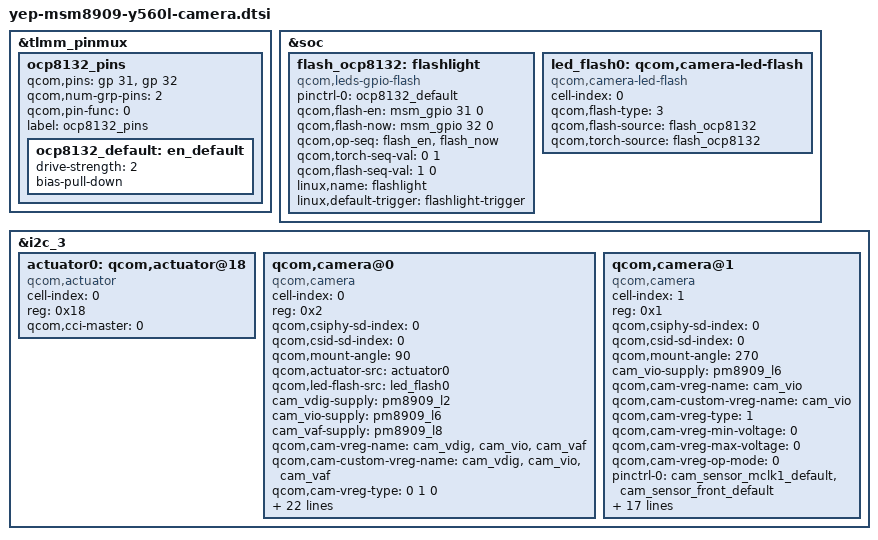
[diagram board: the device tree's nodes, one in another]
/*
 * Copyright (c) 2014, The Linux Foundation. All rights reserved.
 *
 * This program is free software; you can redistribute it and/or modify
 * it under the terms of the GNU General Public License version 2 and
 * only version 2 as published by the Free Software Foundation.
 *
 * This program is distributed in the hope that it will be useful,
 * but WITHOUT ANY WARRANTY; without even the implied warranty of
 * MERCHANTABILITY or FITNESS FOR A PARTICULAR PURPOSE.  See the
 * GNU General Public License for more details.
 */
 
/*  Date            Author          Why
    2014-01-12      litao2          creat
*/ 
 
&tlmm_pinmux {
	ocp8132_pins {
		qcom,pins = <&gp 31>, <&gp 32>;
		qcom,num-grp-pins = <2>;
		qcom,pin-func = <0>;
		label = "ocp8132_pins";
		ocp8132_default: en_default {
		drive-strength = <2>;
		bias-pull-down;
		};
	};
};

&soc {
	flash_ocp8132:flashlight {
		compatible = "qcom,leds-gpio-flash";
		status = "okay";
		pinctrl-names = "flash_default";
		pinctrl-0 = <&ocp8132_default>;
		qcom,flash-en = <&msm_gpio 31 0>;
		qcom,flash-now = <&msm_gpio 32 0>;
		qcom,op-seq = "flash_en", "flash_now";
		qcom,torch-seq-val = <0 1>;
		qcom,flash-seq-val = <1 0>;
		linux,name = "flashlight";
		linux,default-trigger = "flashlight-trigger";
	};
	led_flash0: qcom,camera-led-flash {
		cell-index = <0>;
		compatible = "qcom,camera-led-flash";
		qcom,flash-type = <3>;
		qcom,flash-source = <&flash_ocp8132>;
		qcom,torch-source = <&flash_ocp8132>;
	};
};

&i2c_3 {

	actuator0: qcom,actuator@18 {
		cell-index = <0>;
		reg = <0x18>;
		compatible = "qcom,actuator";
		qcom,cci-master = <0>;
	};
	
	qcom,camera@0 {
		cell-index = <0>;
		compatible = "qcom,camera";
		reg = <0x2>;
		qcom,csiphy-sd-index = <0>;
		qcom,csid-sd-index = <0>;
		qcom,mount-angle = <90>;
		qcom,actuator-src = <&actuator0>;
		qcom,led-flash-src = <&led_flash0>;
		cam_vdig-supply = <&pm8909_l2>;
		cam_vio-supply = <&pm8909_l6>;
		cam_vaf-supply = <&pm8909_l8>;
		qcom,cam-vreg-name = "cam_vdig","cam_vio","cam_vaf";
		qcom,cam-custom-vreg-name = "cam_vdig","cam_vio","cam_vaf";
		qcom,cam-vreg-type = <0 1 0>;
		qcom,cam-vreg-min-voltage = <1200000 0 2850000>;
		qcom,cam-vreg-max-voltage = <1200000 0 2900000>;
		qcom,cam-vreg-op-mode = <200000 0 100000>;
		pinctrl-names = "cam_default", "cam_suspend";
		pinctrl-0 = <&cam_sensor_mclk0_default
				&cam_sensor_rear_default>;
		pinctrl-1 = <&cam_sensor_mclk0_sleep &cam_sensor_rear_sleep>;
		gpios = <&msm_gpio 26 0>,
			<&msm_gpio 35 0>,
			<&msm_gpio 34 0>,
			<&msm_gpio 10 0>,
			<&msm_gpio 93 0>;
		qcom,gpio-reset = <1>;
		qcom,gpio-standby = <2>;
		qcom,gpio-cameraid = <3>;
		qcom,gpio-vana = <4>;
		qcom,gpio-req-tbl-num = <0 1 2 3 4>;
		qcom,gpio-req-tbl-flags = <1 0 0 1 0>;
		qcom,gpio-req-tbl-label = "CAMIF_MCLK",
			"CAM_RESET",
			"CAM_STANDBY",
			"CAM_ID",
			"CAM_VANA";
		qcom,sensor-position = <0>;
		qcom,sensor-mode = <0>;
		qcom,cci-master = <0>;
		status = "ok";
		clocks = <&clock_gcc clk_mclk0_clk_src>,
				<&clock_gcc clk_gcc_camss_mclk0_clk>;
		clock-names = "cam_src_clk", "cam_clk";
	};

	qcom,camera@1 {
		cell-index = <1>;
		compatible = "qcom,camera";
		reg = <0x1>;
		qcom,csiphy-sd-index = <0>;
		qcom,csid-sd-index = <0>;
		qcom,mount-angle = <270>;
		cam_vio-supply = <&pm8909_l6>;
		qcom,cam-vreg-name = "cam_vio";
		qcom,cam-custom-vreg-name = "cam_vio";
		qcom,cam-vreg-type = <1>;
		qcom,cam-vreg-min-voltage = <0>;
		qcom,cam-vreg-max-voltage = <0>;
		qcom,cam-vreg-op-mode = <0>;
		pinctrl-names = "cam_default", "cam_suspend";
		pinctrl-0 = <&cam_sensor_mclk1_default &cam_sensor_front_default>;
		pinctrl-1 = <&cam_sensor_mclk1_sleep &cam_sensor_front_sleep>;
		gpios = <&msm_gpio 27 0>,
			<&msm_gpio 28 0>,
			<&msm_gpio 33 0>,
			<&msm_gpio 9 0>,
			<&msm_gpio 93 0>;
		qcom,gpio-reset = <1>;
		qcom,gpio-standby = <2>;
		qcom,gpio-cameraid = <3>;
		qcom,gpio-vana = <4>;
		qcom,gpio-req-tbl-num = <0 1 2 3 4>;
		qcom,gpio-req-tbl-flags = <1 0 0 1 0>;
		qcom,gpio-req-tbl-label = "CAMIF_MCLK",
			"CAM_RESET",
			"CAM_STANDBY",
			"CAM_ID",
			"CAM_VANA";
		qcom,sensor-position = <1>;
		qcom,sensor-mode = <0>;
		qcom,cci-master = <0>;
		status = "ok";
		clocks = <&clock_gcc clk_mclk1_clk_src>,
				<&clock_gcc clk_gcc_camss_mclk1_clk>;
		clock-names = "cam_src_clk", "cam_clk";
	};
	
};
